# DA1470x register map
Vendor: Dialog; Series: DA1470x; File version: 1.2
CPU: CM33 r0p2, little endian, MPU, FPU, DSP, VTOR, 4 interrupt priority bits
Registers are 32-bit, read-write, reset 0x0 unless marked. A register's access mark holds for its fields unless they carry their own. Offsets are from the block's base; [hi:lo] are bit positions.

## EMMC (part 3 of 3) — EMMC registers
Base 0x30058000
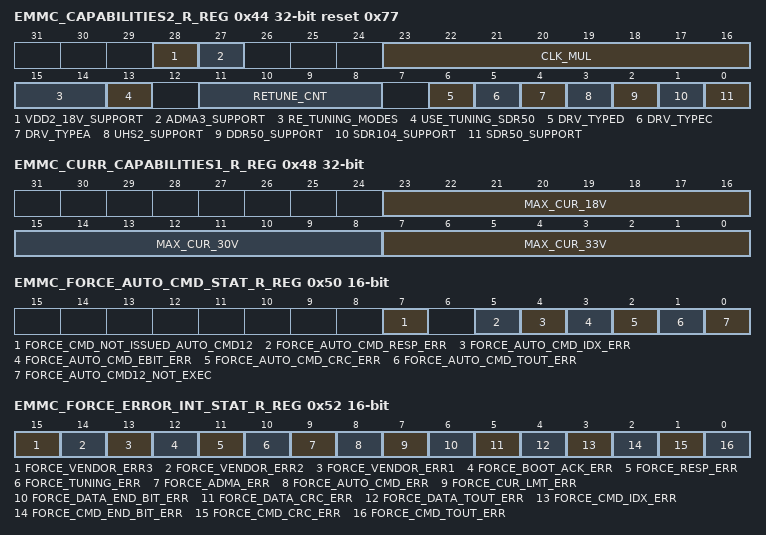
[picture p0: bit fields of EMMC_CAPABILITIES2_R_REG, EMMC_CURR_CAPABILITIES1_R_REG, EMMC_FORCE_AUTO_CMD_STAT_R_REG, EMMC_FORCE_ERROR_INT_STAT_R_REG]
0x44 EMMC_CAPABILITIES2_R_REG reset 0x77 — This register provides the Host Driver with information specific to the Host Controller implementation. The host controller may
  [28] VDD2_18V_SUPPORT ro — 1.8V VDD2 Support This bit indicates support of VDD2 for the Host System. Values: 0x0 (FALSE): 1.8V VDD2 is not Supported 0x1 (TRUE): 1.8V VDD2 is Supported
  [27] ADMA3_SUPPORT ro — ADMA3 Support This bit indicates whether the Host Controller is capable of using ADMA3. Values: 0x0 (FALSE): ADMA3 not Supported 0x1 (TRUE): ADMA3 Supported
  [23:16] CLK_MUL ro — Clock Multiplier These bits indicate the clock multiplier of the programmable clock generator. Setting these bits to 0 means that the Host Controller does not support a programmable clock generator. - 0x0: Clock Multiplier is not Supported - 0x1: Clock Multiplier M = 2 - 0x2: Clock Multiplier M = 3 - ......... - 0xFF: Clock Multiplier M = 256
  [15:14] RE_TUNING_MODES ro — Re-Tuning Modes (UHS-I only) These bits select the re-tuning method and limit the maximum data length. Values: 0x0 (MODE1): Timer 0x1 (MODE2): Timer and Re-Tuning Request (Not supported) 0x2 (MODE3): Auto Re-Tuning (for transfer) 0x3 (RSVD_MODE): Reserved
  [13] USE_TUNING_SDR50 ro — Use Tuning for SDR50 (UHS-I only)
  [11:8] RETUNE_CNT ro — Timer Count for Re-Tuning (UHS-I only) - 0x0: Re-Tuning Timer disabled - 0x1: 1 seconds - 0x2: 2 seconds - 0x3: 4 seconds - ........ - 0xB: 1024 seconds - 0xC: Reserved - 0xD: Reserved - 0xE: Reserved - 0xF: Get information from other source
  [6] DRV_TYPED ro — Driver Type D Support (UHS-I only) This bit indicates support of Driver Type D for 1.8 Signaling. Values: Description 0x0 (FALSE): Driver Type D is not supported 0x1 (TRUE): Driver Type D is supported
  [5] DRV_TYPEC ro — Driver Type C Support (UHS-I only) This bit indicates support of Driver Type C for 1.8 Signaling. Values: 0x0 (FALSE): Driver Type C is not supported 0x1 (TRUE): Driver Type C is supported
  [4] DRV_TYPEA ro — Driver Type A Support (UHS-I only) This bit indicates support of Driver Type A for 1.8 Signaling. Values: 0x0 (FALSE): Driver Type A is not supported 0x1 (TRUE): Driver Type A is supported
  [3] UHS2_SUPPORT ro — UHS-II Support (UHS-II only) This bit indicates whether Host Controller supports UHS-II. Values: 0x0 (FALSE): UHS-II is not supported 0x1 (TRUE): UHS-II is supported
  [2] DDR50_SUPPORT ro — DDR50 Support (UHS-I only) Values: 0x0 (FALSE): DDR50 is not supported 0x1 (TRUE): DDR50 is supported
  [1] SDR104_SUPPORT ro — SDR104 Support (UHS-I only) This bit mentions that SDR104 requires tuning. Values: 0x0 (FALSE): SDR104 is not supported 0x1 (TRUE): SDR104 is supported
  [0] SDR50_SUPPORT ro — SDR50 Support (UHS-I only) Thsi bit indicates that SDR50 is supported. The bit 13 (USE_TUNING_SDR50) indicates whether SDR50 requires tuning or not. Values: 0x0 (FALSE): SDR50 is not supported 0x1 (TRUE): SDR50 is supported
0x48 EMMC_CURR_CAPABILITIES1_R_REG — This register indicate the maximum current capability for each voltage, for VDD1. The value is meaningful if the Voltage Suppor
  [23:16] MAX_CUR_18V ro — Maximum Current for 1.8V This bit specifies the Maximum Current for 1.8V VDD1 power supply for the card. - 0: Get information through another method - 1: 4mA - 2: 8mA - 3: 13mA - ....... - 255: 1020mA
  [15:8] MAX_CUR_30V ro — Maximum Current for 3.0V This bit specifies the Maximum Current for 3.0V VDD1 power supply for the card. - 0: Get information through another method - 1: 4mA - 2: 8mA - 3: 13mA - ....... - 255: 1020mA
  [7:0] MAX_CUR_33V ro — Maximum Current for 3.3V This bit specifies the Maximum Current for 3.3V VDD1 power supply for the card. - 0: Get information through another method - 1: 4mA - 2: 8mA - 3: 13mA - ....... - 255: 1020mA
0x4C EMMC_CURR_CAPABILITIES2_R_REG — This register indicates the maximum current capability for each voltage (for VDD2). The value is meaningful if Voltage Support
  [7:0] MAX_CUR_VDD2_18V ro — Maximum Current for 1.8V VDD2 This bit specifies the Maximum Current for 1.8V VDD2 power supply for the UHS-II card. - 0: Get information through another method - 1: 4mA - 2: 8mA - 3: 13mA - ....... - 255: 1020mA
0x50 EMMC_FORCE_AUTO_CMD_STAT_R_REG 16-bit — The register is not a physically implemented but is an address at which the Auto CMD Error Status register can be written.This
  [7] FORCE_CMD_NOT_ISSUED_AUTO_CMD12 wo — Force Event for Command Not Issued By Auto CMD12 Error Values: 0x1 (TRUE): Command Not Issued By Auto CMD12 Error Status is set 0x0 (FALSE): Not Affected
  [5] FORCE_AUTO_CMD_RESP_ERR wo — Force Event for Auto CMD Response Error Values: 0x1 (TRUE): Auto CMD Response Error Status is set 0x0 (FALSE): Not Affected
  [4] FORCE_AUTO_CMD_IDX_ERR wo — Force Event for Auto CMD Index Error Values: 0x1 (TRUE): Auto CMD Index Error Status is set 0x0 (FALSE): Not Affected
  [3] FORCE_AUTO_CMD_EBIT_ERR wo — Force Event for Auto CMD End Bit Error Values: 0x1 (TRUE): Auto CMD End Bit Error Status is set 0x0 (FALSE): Not Affected
  [2] FORCE_AUTO_CMD_CRC_ERR wo — Force Event for Auto CMD CRC Error Values: 0x1 (TRUE): Auto CMD CRC Error Status is set 0x0 (FALSE): Not Affected
  [1] FORCE_AUTO_CMD_TOUT_ERR wo — Force Event for Auto CMD Timeout Error Values: 0x1 (TRUE): Auto CMD Timeout Error Status is set 0x0 (FALSE): Not Affected
  [0] FORCE_AUTO_CMD12_NOT_EXEC wo — Force Event for Auto CMD12 Not Executed Values: 0x1 (TRUE): Auto CMD12 Not Executed Status is set 0x0 (FALSE): Not Affected
0x52 EMMC_FORCE_ERROR_INT_STAT_R_REG 16-bit — This register is not physically implemented but is an address at which the Error Interrupt Status register can be written. The
  [15] FORCE_VENDOR_ERR3 wo — This bit (FORCE_VENDOR_ERR3) of the FORCE_ERROR_INT_STAT_R register is reserved. It always returns 0.
  [14] FORCE_VENDOR_ERR2 wo — This bit (FORCE_VENDOR_ERR2) of the FORCE_ERROR_INT_STAT_R register is reserved. It always returns 0.
  [13] FORCE_VENDOR_ERR1 wo — This bit (FORCE_VENDOR_ERR1) of the FORCE_ERROR_INT_STAT_R register is reserved. It always returns 0.
  [12] FORCE_BOOT_ACK_ERR wo — Force Event for Boot Ack error Values: 0x0 (FALSE): Not Affected 0x1 (TRUE): Boot ack Error Status is set
  [11] FORCE_RESP_ERR wo — Force Event for Response Error (SD Mode only) Values: 0x0 (FALSE): Not Affected 0x1 (TRUE): Response Error Status is set
  [10] FORCE_TUNING_ERR wo — Force Event for Tuning Error (UHS-I Mode only)
  [9] FORCE_ADMA_ERR wo — Force Event for ADMA Error Values: 0x0 (FALSE): Not Affected 0x1 (TRUE): ADMA Error Status is set
  [8] FORCE_AUTO_CMD_ERR wo — Force Event for Auto CMD Error (SD/eMMC Mode only) Values: 0x0 (FALSE): Not Affected 0x1 (TRUE): ADMA Error Status is set
  [7] FORCE_CUR_LMT_ERR wo — Force Event for Current Limit Error Values: 0x0 (FALSE): Not Affected 0x1 (TRUE): Current Limit Error Status is set
  [6] FORCE_DATA_END_BIT_ERR wo — Force Event for Data End Bit Error (SD/eMMC Mode only) Values: 0x0 (FALSE): Not Affected 0x1 (TRUE): Data End Bit Error Status is set
  [5] FORCE_DATA_CRC_ERR wo — Force Event for Data CRC Error (SD/eMMC Mode only) Values: 0x0 (FALSE): Not Affected 0x1 (TRUE): Data CRC Error Status is set
  [4] FORCE_DATA_TOUT_ERR wo — Force Event for Data Timeout Error (SD/eMMC Mode only) Values: 0x0 (FALSE): Not Affected 0x1 (TRUE): Data Timeout Error Status is set
  [3] FORCE_CMD_IDX_ERR wo — Force Event for Command Index Error (SD/eMMC Mode only) Values: 0x0 (FALSE): Not Affected 0x1 (TRUE): Command Index Error Status is set
  [2] FORCE_CMD_END_BIT_ERR wo — Force Event for Command End Bit Error (SD/eMMC Mode only) Values: 0x0 (FALSE): Not Affected 0x1 (TRUE): Command End Bit Error Status is set
  [1] FORCE_CMD_CRC_ERR wo — Force Event for Command CRC Error (SD/eMMC Mode only) Values: 0x0 (FALSE): Not Affected 0x1 (TRUE): Command CRC Error Status is set
  [0] FORCE_CMD_TOUT_ERR wo — Force Event for Command Timeout Error (SD/eMMC Mode only) Values: 0x0 (FALSE): Not Affected 0x1 (TRUE): Command Timeout Error Status is set
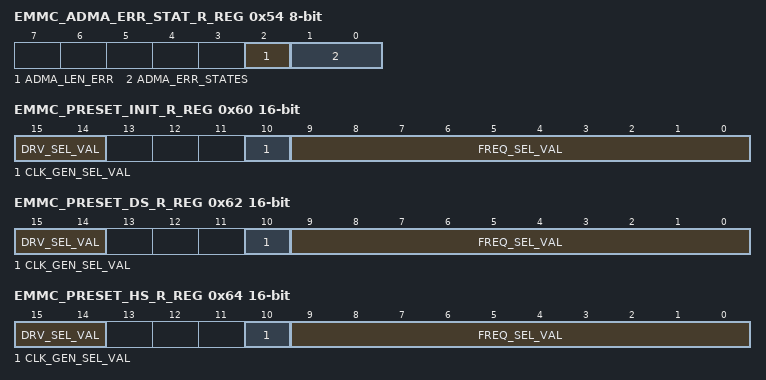
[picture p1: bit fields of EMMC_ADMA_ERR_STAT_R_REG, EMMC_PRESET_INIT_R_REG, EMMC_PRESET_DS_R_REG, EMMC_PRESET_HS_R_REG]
0x54 EMMC_ADMA_ERR_STAT_R_REG 8-bit — This register stores the ADMA state during an ADMA error. This register is applicable for an SD/eMMC/UHS-II mode.
  [2] ADMA_LEN_ERR ro — ADMA Length Mismatch Error States This error occurs in the following instances: - While the Block Count Enable is being set, the total data length specified by the Descriptor table is different from that specified by the Block Count and Block Length - When the total data length cannot be divided by the block length Values: 0x0 (NO_ERR): No Error 0x1 (ERROR): Error
  [1:0] ADMA_ERR_STATES ro — ADMA Error States These bits indicate the state of ADMA when an error occurs during ADMA data transfer. Values: 0x0 (ST_STOP): Stop DMA - SYS_ADR register points to a location next to the error descriptor 0x1 (ST_FDS): Fetch Descriptor - SYS_ADR register points to the error descriptor 0x2 (UNUSED): Never set this state 0x3 (ST_TFR): Transfer Data - SYS_ADR register points to a location next to the error descriptor
0x58 EMMC_ADMA_SA_LOW_R_REG (reset mask 0x7FFFFFFF) — This register holds the lower 32-bit system address for DMA transfer. This register is applicable for an SD/eMMC/UHS-II mode.
  [31:0] ADMA_SA_LOW — ADMA System Address These bits indicate the lower 32 bits of the ADMA system address. - SDMA: If Host Version 4 Enable is set to 1, this register stores the system address of the data location - ADMA2: This register stores the byte address of the executing command of the descriptor table - ADMA3: This register is set by ADMA3. ADMA2 increments the address of this register that points to the next line, every time a Descriptor line is fetched.
0x60 EMMC_PRESET_INIT_R_REG 16-bit — This register defines Preset Value for Initialization in SD/eMMC mode.
  [15:14] DRV_SEL_VAL ro — Driver Strength Select Value These bits indicate that the Driver strength is supported by 1.8V signaling bus speed modes. These bits are meaningless for 3.3V signaling. Values: 0x0 (TYPEB): Driver Type B is selected 0x1 (TYPEA): Driver Type A is selected 0x2 (TYPEC): Driver Type C is selected 0x3 (TYPED): Driver Type D is selected
  [10] CLK_GEN_SEL_VAL ro — Clock Generator Select Value This bit is effective when the Host Controller supports a programmable clock generator. Values: 0x0 (FALSE): Host Controller Ver2.0 Compatible Clock Generator 0x1 (PROG): Programmable Clock Generator
  [9:0] FREQ_SEL_VAL ro — SDCLK/RCLK Frequency Select Value 10-bit preset value to be set in SDCLK/RCLK Frequency Select field of the Clock Control register described by a Host System.
0x62 EMMC_PRESET_DS_R_REG 16-bit — This register defines Preset Value for Default Speed mode in SD mode.
  [15:14] DRV_SEL_VAL ro — Driver Strength Select Value These bits indicate the Driver strength value supported by 1.8V signaling bus speed modes. This field is meaningless for the Default speed mode as it uses 3.3V signaling. Values: 0x0 (TYPEB): Driver Type B is selected 0x1 (TYPEA): Driver Type A is selected 0x2 (TYPEC): Driver Type C is selected 0x3 (TYPED): Driver Type D is selected
  [10] CLK_GEN_SEL_VAL ro — Clock Generator Select Value This bit is effective when Host Controller supports programmable clock generator. Values: 0x0 (FALSE): Host Controller Ver2.0 Compatible Clock Generator 0x1 (PROG): Programmable Clock Generator
  [9:0] FREQ_SEL_VAL ro — SDCLK/RCLK Frequency Select Value 10-bit preset value to be set in SDCLK/RCLK Frequency Select field of the Clock Control register described by a Host System.
0x64 EMMC_PRESET_HS_R_REG 16-bit — This register defines Preset Value for High Speed mode in SD mode.
  [15:14] DRV_SEL_VAL ro — Driver Strength Select Value These bits indicate the Driver strength value supported by 1.8V signaling bus speed modes. This field is meaningless for High speed mode as it uses 3.3V signaling. Values: 0x0 (TYPEB): Driver Type B is selected 0x1 (TYPEA): Driver Type A is selected 0x2 (TYPEC): Driver Type C is selected 0x3 (TYPED): Driver Type D is selected
  [10] CLK_GEN_SEL_VAL ro — Clock Generator Select Value This bit is effective when Host Controller supports programmable clock generator. Values: 0x0 (FALSE): Host Controller Ver2.0 Compatible Clock Generator 0x1 (PROG): Programmable Clock Generator
  [9:0] FREQ_SEL_VAL ro — SDCLK/RCLK Frequency Select Value 10-bit preset value to be set in SDCLK/RCLK Frequency Select field of the Clock Control register described by a Host System.
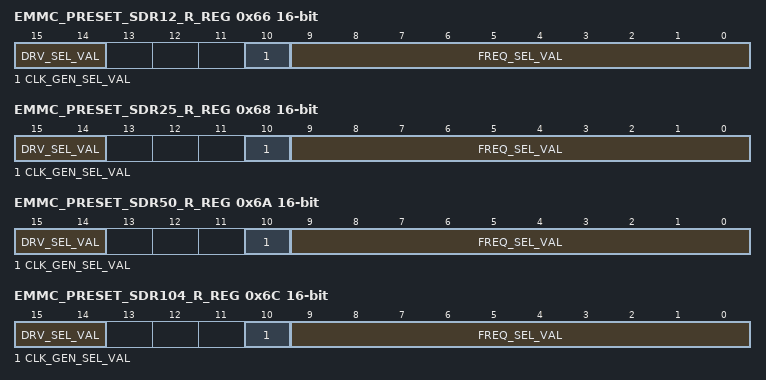
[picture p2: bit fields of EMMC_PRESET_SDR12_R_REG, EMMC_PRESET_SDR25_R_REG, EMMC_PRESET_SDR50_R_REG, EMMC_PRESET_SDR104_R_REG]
0x66 EMMC_PRESET_SDR12_R_REG 16-bit — This register defines Preset Value for SDR12 and Legacy speed mode in SD and eMMC mode respectively.
  [15:14] DRV_SEL_VAL ro — Driver Strength Select Value These bits indicate the Driver strength value supported for the SDR12 bus speed mode. These bits are meaningless for 3.3V signaling. Values: 0x0 (TYPEB): Driver Type B is selected 0x1 (TYPEA): Driver Type A is selected 0x2 (TYPEC): Driver Type C is selected 0x3 (TYPED): Driver Type D is selected
  [10] CLK_GEN_SEL_VAL ro — Clock Generator Select Value This bit is effective when Host Controller supports programmable clock generator Values: 0x0 (FALSE): Host Controller Ver2.0 Compatible Clock Generator 0x1 (PROG): Programmable Clock Generator
  [9:0] FREQ_SEL_VAL ro — SDCLK/RCLK Frequency Select Value 10-bit preset value to be set in SDCLK/RCLK Frequency Select field of the Clock Control register described by a Host System.
0x68 EMMC_PRESET_SDR25_R_REG 16-bit — This register defines Preset Value for SDR25 and High Speed SDR speed mode in SD and eMMC mode respectively.
  [15:14] DRV_SEL_VAL ro — Driver Strength Select Value These bits indicate the Driver strength value supported for the SDR25 bus speed mode. These bits are meaningless for 3.3V signaling. Values: 0x0 (TYPEB): Driver Type B is selected 0x1 (TYPEA): Driver Type A is selected 0x2 (TYPEC): Driver Type C is selected 0x3 (TYPED): Driver Type D is selected
  [10] CLK_GEN_SEL_VAL ro — Clock Generator Select Value This bit is effective when Host Controller supports programmable clock generator. Values: 0x0 (FALSE): Host Controller Ver2.0 Compatible Clock Generator 0x1 (PROG): Programmable Clock Generator
  [9:0] FREQ_SEL_VAL ro — SDCLK/RCLK Frequency Select Value 10-bit preset value to be set in SDCLK/RCLK Frequency Select field of the Clock Control register described by a Host System.
0x6A EMMC_PRESET_SDR50_R_REG 16-bit — This register defines Preset Value for SDR50 speed mode in SD mode.
  [15:14] DRV_SEL_VAL ro — Driver Strength Select Value These bits indicate Driver strength value supported for SDR50 bus speed mode. These bits are meaningless for 3.3V signaling. Values: 0x0 (TYPEB): Driver Type B is selected 0x1 (TYPEA): Driver Type A is selected 0x2 (TYPEC): Driver Type C is selected 0x3 (TYPED): Driver Type D is selected
  [10] CLK_GEN_SEL_VAL ro — Clock Generator Select Value This bit is effective when Host Controller supports programmable clock generator. Values: 0x0 (FALSE): Host Controller Ver2.0 Compatible Clock Generator 0x1 (PROG): Programmable Clock Generator
  [9:0] FREQ_SEL_VAL ro — SDCLK/RCLK Frequency Select Value 10-bit preset value to be set in SDCLK/RCLK Frequency Select field of the Clock Control register described by a Host System.
0x6C EMMC_PRESET_SDR104_R_REG 16-bit — This register defines Preset Value for SDR104 and HS200 speed modes in the SD and eMMC modes, respectively.
  [15:14] DRV_SEL_VAL ro — Driver Strength Select Value These bits indicate Driver strength value supported for SDR104 bus speed mode. These bits are meaningless for 3.3V signaling. Values: 0x0 (TYPEB): Driver Type B is selected 0x1 (TYPEA): Driver Type A is selected 0x2 (TYPEC): Driver Type C is selected 0x3 (TYPED): Driver Type D is selected
  [10] CLK_GEN_SEL_VAL ro — Clock Generator Select Value This bit is effective when Host Controller supports programmable clock generator. Values: 0x0 (FALSE): Host Controller Ver2.0 Compatible Clock Generator 0x1 (PROG): Programmable Clock Generator
  [9:0] FREQ_SEL_VAL ro — SDCLK/RCLK Frequency Select Value These bits specify a 10-bit preset value that must be set in the SDCLK/RCLK Frequency Select field of the Clock Control register described by a Host System.
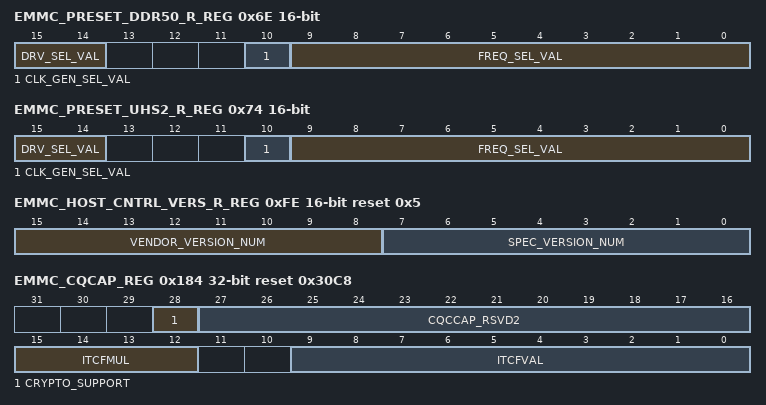
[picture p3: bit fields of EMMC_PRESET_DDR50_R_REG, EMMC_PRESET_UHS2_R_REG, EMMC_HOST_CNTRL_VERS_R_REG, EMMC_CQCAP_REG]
0x6E EMMC_PRESET_DDR50_R_REG 16-bit — This register defines the Preset Value for DDR50 and High Speed DDR speed modes in the SD and eMMC modes, respectively.
  [15:14] DRV_SEL_VAL ro — Driver Strength Select Value These bits indicate Driver strength value supported for DDR50 bus speed mode. These bits are meaningless for 3.3V signaling. Values: 0x0 (TYPEB): Driver Type B is selected 0x1 (TYPEA): Driver Type A is selected 0x2 (TYPEC): Driver Type C is selected 0x3 (TYPED): Driver Type D is selected
  [10] CLK_GEN_SEL_VAL ro — Clock Generator Select Value This bit is effective when Host Controller supports programmable clock generator. Values: 0x0 (FALSE): Host Controller Ver2.0 Compatible Clock Generator 0x1 (PROG): Programmable Clock Generator
  [9:0] FREQ_SEL_VAL ro — SDCLK/RCLK Frequency Select Value These bits specify a 10-bit preset value that must be set in the SDCLK/RCLK Frequency Select field of the Clock Control register, as described by a Host System.
0x74 EMMC_PRESET_UHS2_R_REG 16-bit — This register is used to hold the preset value for UHS-II and HS400 speed modes in the SD and eMMC modes, respectively.
  [15:14] DRV_SEL_VAL ro — Driver Strength Select Value These bits indicate the Driver strength value supported by 1.8V signaling bus speed modes in the SD mode. This field is meaningless for UHS-II mode. In eMMC mode, these bits can be used for selecting the Drive strength value for HS400 mode. Values: 0x0 (TYPEB): Driver Type B is selected 0x1 (TYPEA): Driver Type A is selected 0x2 (TYPEC): Driver Type C is selected 0x3 (TYPED): Driver Type D is selected
  [10] CLK_GEN_SEL_VAL ro — Clock Generator Select Value This bit is effective when the Host Controller supports a programmable clock generator. Values: 0x0 (FALSE): Host Controller Ver2.0 Compatible Clock Generator 0x1 (PROG): Programmable Clock Generator
  [9:0] FREQ_SEL_VAL ro — SDCLK/RCLK Frequency Select Value These bits specify the 10-bit preset value that must be set in the SDCLK/RCLK Frequency Select field of the Clock Control register, as described by a Host System.
0xE6 EMMC_P_EMBEDDED_CNTRL_REG 16-bit reset 0xF6C — This register points to the location of UHS-II embedded control registers.
  [11:0] REG_OFFSET_EMBEDDED_CNTRL_ADDR ro — Offset Address of Embedded Control register.
0xE8 EMMC_P_VENDOR_SPECIFIC_AREA_REG 16-bit reset 0x500 — This register used as a pointer for the Vendor Specific Area 1.
  [11:0] REG_OFFSET_ADDR_VENDOR ro — Base offset Address for Vendor-Specific registers.
0xEA EMMC_P_VNDR2_SPECIFIC_AREA_REG 16-bit reset 0x180 — This register is used as a pointer for the Vendor Specific Area 2.
  [15:0] REG_OFFSET_ADDR_VNDR2 ro — Base offset Address for Command Queuing registers.
0xFC EMMC_SLOT_INTR_STATUS_R_REG 16-bit — This register indicates the Interrupt status of each slot.
  [7:0] INTR_SLOT ro — Interrupt signal for each Slot These status bits indicate the logical OR of Interrupt signal and Wakeup signal for each slot. A maximum of 8 slots can be defined. If one interrupt signal is associated with multiple slots, the Host Driver can identify the interrupt that is generated by reading these bits. By a power on reset or by setting Software Reset For All bit, the interrupt signals are de-asserted and this status reads 00h. - Bit 00: Slot 1 - Bit 01: Slot 2 - Bit 02: Slot 3 - .......... - .......... - Bit 07: Slot 8 Note: MSHC Host Controller support single card slot. This register shall always return 0.
0xFE EMMC_HOST_CNTRL_VERS_R_REG 16-bit reset 0x5 — This register is used to indicate the Host Controller Version number.
  [15:8] VENDOR_VERSION_NUM ro — Vendor Version Number This field is reserved for the vendor version number. Host Driver must not use this status.
  [7:0] SPEC_VERSION_NUM ro — Specification Version Number These bits indicate the Host controller specification version. The upper and lower 4-bits indicate the version. Values 0x06-0xFF are reserved. Values: 0x0 (VER_1_00): SD Host Controller Specification Version 1.00 0x1 (VER_2_00): SD Host Controller Specification Version 2.00 0x2 (VER_3_00): SD Host Controller Specification Version 3.00 0x3 (VER_4_00): SD Host Controller Specification Version 4.00 0x4 (VER_4_10): SD Host Controller Specification Version 4.10 0x5 (VER_4_20): SD Host Controller Specification Version 4.20
0x184 EMMC_CQCAP_REG reset 0x30C8 — This register indicates the capabilities of the command queuing engine.
  [28] CRYPTO_SUPPORT ro — Crypto Support This bit indicates whether the Host Controller supports cryptographic operations. Values: 0x0 (FALSE): Crypto not Supported 0x1 (TRUE): Crypto Supported
  [27:16] CQCCAP_RSVD2 ro — These bits [27:16] of the CQCAP register are reserved. They always return 0.
  [15:12] ITCFMUL ro — Internal Timer Clock Frequency Multiplier (ITCFMUL) This field indicates the frequency of the clock used for interrupt coalescing timer and for determining the SQS polling period. See ITCFVAL definition for details. Values 0x5 to 0xF are reserved. Values: 0x0 (CLK_1KHz): 1KHz clock 0x1 (CLK_10KHz): 10KHz clock 0x2 (CLK_100KHz): 100KHz clock 0x3 (CLK_1MHz): 1MHz clock 0x4 (CLK_10MHz): 10MHz clock
  [9:0] ITCFVAL ro — Internal Timer Clock Frequency Value (ITCFVAL) This field scales the frequency of the timer clock provided by ITCFMUL. The Final clock frequency of actual timer clock is calculated as ITCFVAL* ITCFMUL.
0x500 EMMC_MSHC_VER_ID_R_REG reset 0x3138302A (reset mask 0x7FFFFFFF) — This register reflects the current release number of DWC_mshc/DWC_mshc_lite.
  [31:0] MSHC_VER_ID ro — Current release number This field indicates the Synopsys DesignWare Cores DWC_mshc/DWC_mshc_lite current release number that is read by an application. An application reading this register in conjunction with the MSHC_VER_TYPE_R register, gathers details of the current release.
0x504 EMMC_MSHC_VER_TYPE_R_REG reset 0x67612A2A (reset mask 0x7FFFFFFF) — This register reflects the current release type of DWC_mshc/DWC_mshc_lite.
  [31:0] MSHC_VER_TYPE ro — Current release type This field indicates the Synopsys DesignWare Cores DWC_mshc/DWC_mshc_lite current release type that is read by an application. An application reading this register in conjunction with the MSHC_VER_ID_R register, gathers details of the current release.
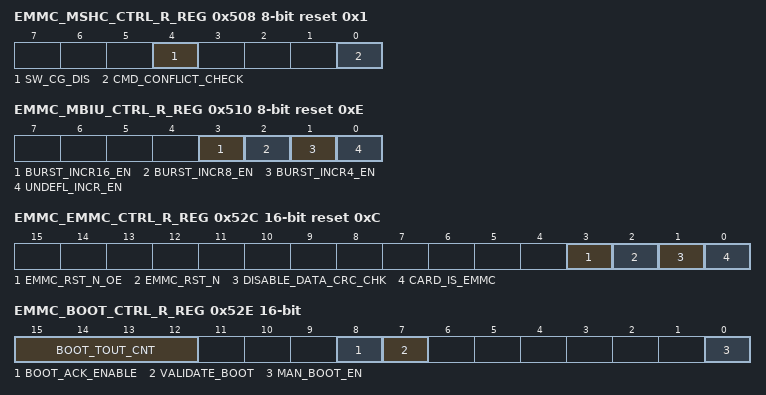
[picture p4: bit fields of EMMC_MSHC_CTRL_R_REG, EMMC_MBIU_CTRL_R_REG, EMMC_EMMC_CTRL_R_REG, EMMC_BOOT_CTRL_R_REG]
0x508 EMMC_MSHC_CTRL_R_REG 8-bit reset 0x1 — This register is used to control the operation of MSHC Host Controller.
  [4] SW_CG_DIS — Internal clock gating disable control This bit must be used to disable IP's internal clock gating when required. when disabled clocks are not gated. Clocks to the core (except hclk) must be stopped when programming this bit. Values: 0x0 (ENABLE): Internal clock gates are active and clock gating is controlled internally 0x1 (DISABLE): Internal clock gating is disabled, clocks are not gated internally
  [0] CMD_CONFLICT_CHECK — Command conflict check This bit enables command conflict check. Note: DWC_mshc controller monitors the CMD line whenever a command is issued and checks whether the value driven on sd_cmd_out matches the value on sd_cmd_in at next subsequent edge of cclk_tx to determine command conflict error. This bit is cleared only if the feed back delay (including IO Pad delay) is more than (t_card_clk_period - t_setup), where t_setup is the setup time of a flop in DWC_mshc. The I/O pad delay is consistent across CMD and DATA lines, and it is within the value: (2*t_card_clk_period - t_setup) Values: 0x0 (DISABLE_CMD_CONFLICT_CHK): Disable command conflict check 0x1 (CMD_CONFLICT_CHK_LAT1): Check for command conflict after 1 card clock cycle
0x510 EMMC_MBIU_CTRL_R_REG 8-bit reset 0xE — This register is used to select the valid burst types that the AHB Master bus interface can generate. When more than one bit
  [3] BURST_INCR16_EN — INCR16 Burst Controls generation of INCR16 transfers on Master interface. Values: 0x0 (FALSE): AHB INCR16 burst type is not generated on Master I/F 0x1 (TRUE): AHB INCR16 burst type can be generated on Master I/F
  [2] BURST_INCR8_EN — INCR8 Burst Controls generation of INCR8 transfers on Master interface. Values: 0x0 (FALSE): AHB INCR8 burst type is not generated on Master I/F 0x1 (TRUE): AHB INCR8 burst type can be generated on Master I/F
  [1] BURST_INCR4_EN — INCR4 Burst Controls generation of INCR4 transfers on Master interface. Values: 0x0 (FALSE): AHB INCR4 burst type is not generated on Master I/F 0x1 (TRUE): AHB INCR4 burst type can be generated on Master I/F
  [0] UNDEFL_INCR_EN — Undefined INCR Burst Controls generation of undefined length INCR transfer on Master interface. Values: 0x0 (FALSE): Undefined INCR type burst is the least preferred burst on AHB Master I/F 0x1 (TRUE): Undefined INCR type burst is the most preferred burst on AHB Master I/F
0x52C EMMC_EMMC_CTRL_R_REG 16-bit reset 0xC — This register is used to control the eMMC operation.
  [3] EMMC_RST_N_OE — Output Enable control for EMMC Device Reset signal PAD control. This field drived sd_rst_n_oe output of DWC_mshc Values: 0x1 (ENABLE): sd_rst_n_oe is 1 0x0 (DISABLE): sd_rst_n_oe is 0
  [2] EMMC_RST_N — EMMC Device Reset signal control. This register field controls the sd_rst_n output of DWC_mshc Values: 0x1 (RST_DEASSERT): Reset to eMMC device is deasserted 0x0 (RST_ASSERT): Reset to eMMC device asserted (active low)
  [1] DISABLE_DATA_CRC_CHK — Disable Data CRC Check This bit controls masking of CRC16 error for Card Write in eMMC mode. This is useful in bus testing (CMD19) for an eMMC device. In bus testing, an eMMC card does not send CRC status for a block, which may generate CRC error. This CRC error can be masked using this bit during bus testing. Values: 0x1 (DISABLE): DATA CRC check is disabled 0x0 (ENABLE): DATA CRC check is enabled
  [0] CARD_IS_EMMC — eMMC Card present This bit indicates the type of card connected. An application program this bit based on the card connected to MSHC. Values: 0x1 (EMMC_CARD): Card connected to MSHC is an eMMC card 0x0 (NON_EMMC_CARD): Card connected to MSHC is a non-eMMC card
0x52E EMMC_BOOT_CTRL_R_REG 16-bit — This register is used to control the eMMC Boot operation.
  [15:12] BOOT_TOUT_CNT — Boot Ack Timeout Counter Value. This value determines the interval by which boot ack timeout (50 ms) is detected when boot ack is expected during boot operation. - 0xF : Reserved - 0xE : TMCLK x 2^27 - .. - ............ - 0x1 : TMCLK x 2^14 - 0x0 : TMCLK x 2^13
  [8] BOOT_ACK_ENABLE — Boot Acknowledge Enable When this bit set, DWC_mshc checks for boot acknowledge start pattern of 0-1-0 during boot operation. This bit is applicable for both mandatory and alternate boot mode. Values: 0x1 (TRUE): Boot Ack enable 0x0 (FALSE): Boot Ack disable
  [7] VALIDATE_BOOT wo — Validate Mandatory Boot Enable bit This bit is used to validate the MAN_BOOT_EN bit. Values: 0x1 (TRUE): Validate Mandatory boot enable bit 0x0 (FALSE): Ignore Mandatory boot Enable bit
  [0] MAN_BOOT_EN — Mandatory Boot Enable This bit is used to initiate the mandatory boot operation. The application sets this bit along with VALIDATE_BOOT bit. Writing 0 is ignored. The DWC_mshc clears this bit after the boot transfer is completed or terminated. Values: 0x1 (MAN_BOOT_EN): Mandatory boot enable 0x0 (MAN_BOOT_DIS): Mandatory boot disable
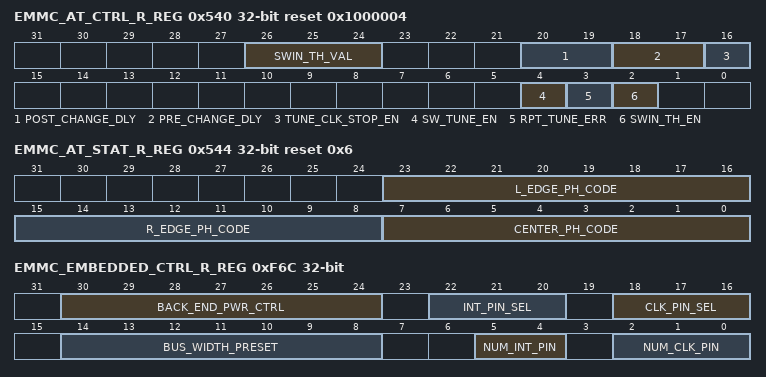
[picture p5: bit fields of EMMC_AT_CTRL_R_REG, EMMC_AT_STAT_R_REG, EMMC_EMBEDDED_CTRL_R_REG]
0x540 EMMC_AT_CTRL_R_REG reset 0x1000004 — This register controls some aspects of tuning and auto-tuning features. Do not program this register when HOST_CTRL2_R.SAMPLE_C
  [26:24] SWIN_TH_VAL — Sampling window threshold value setting The maximum value that can be set here depends on the length of delayline used for tuning. A delayLine with 128 taps can use values from 0x0 to 0x7F. This field is valid only when SWIN_TH_EN is '1'. Should be programmed only when SAMPLE_CLK_SEL is '0' - 0x0 : Threshold values is 0x1, windows of length 1 tap and above can be selected as sampling window. - 0x1 : Threshold values is 0x2, windows of length 2 taps and above can be selected as sampling window. - 0x2 : Threshold values is 0x1, windows of length 3 taps and above can be selected as sampling window. - ........ - 0x7F : Threshold values is 0x1, windows of length 127 taps and above can be selected as sampling window.
  [20:19] POST_CHANGE_DLY — Time taken for phase switching and stable clock output. Specifies the maximum time (in terms of cclk cycles) that the delay line can take to switch its output phase after a change in tuning_cclk_sel or autotuning_cclk_sel. Values: 0x0 (LATENCY_LT_1): Less than 1-cycle latency 0x1 (LATENCY_LT_2): Less than 2-cycle latency 0x2 (LATENCY_LT_3): Less than 3-cycle latency 0x3 (LATENCY_LT_4): Less than 4-cycle latency
  [18:17] PRE_CHANGE_DLY — Maximum Latency specification between cclk_tx and cclk_rx. Values: 0x0 (LATENCY_LT_1): Less than 1-cycle latency 0x1 (LATENCY_LT_2): Less than 2-cycle latency 0x2 (LATENCY_LT_3): Less than 3-cycle latency 0x3 (LATENCY_LT_4): Less than 4-cycle latency
  [16] TUNE_CLK_STOP_EN — Clock stopping control for Tuning and auto-tuning circuit. When enabled, clock gate control output of DWC_mshc (clk2card_on) is pulled low before changing phase select codes on tuning_cclk_sel and autotuning_cclk_sel. This effectively stops the Device/Card clock, cclk_rx and also drift_cclk_rx. Changing phase code when clocks are stopped ensures glitch free phase switching. Set this bit to 0 if the PHY or delayline can guarantee glitch free switching. Values: 0x1 (ENABLE_CLK_STOPPING): Clocks stopped during phase code change 0x0 (DISABLE_CLK_STOPPING): Clocks not stopped. PHY ensures glitch free phase switching.
  [4] SW_TUNE_EN — This fields enables software-managed tuning flow. Values: 0x1 (SW_TUNING_ENABLE): Software-managed tuning enabled. AT_STAT_R.CENTER_PH_CODE Field is now writable. 0x0 (SW_TUNING_DISABLE): Software-managed tuning disabled.
  [3] RPT_TUNE_ERR — Framing errors are not generated when executing tuning. This debug bit allows users to report these errors. Values: 0x1 (DEBUG_ERRORS): Debug mode for reporting framing errors 0x0 (ERRORS_DISABLED): Default mode where as per SD-HCI no errors are reported.
  [2] SWIN_TH_EN — Sampling window Threshold enable Selects the tuning mode Field should be programmed only when SAMPLE_CLK_SEL is '0' Values: 0x1 (THRESHOLD_MODE): Tuning engine selects the first complete sampling window that meets the threshold set by SWIN_TH_VAL field 0x0 (LARGEST_WIN_MODE): Tuning engine sweeps all taps and settles at the largest window
0x544 EMMC_AT_STAT_R_REG reset 0x6 — Register to read the Center, Left and Right codes used by tuning and auto-tuning engines. Center code field is also used for so
  [23:16] L_EDGE_PH_CODE ro — Left Edge Phase code. Reading this field returns the phase code value used by Auto-tuning engine to sample data on Left edge of sampling window.
  [15:8] R_EDGE_PH_CODE ro — Right Edge Phase code. Reading this field returns the phase code value used by Auto-tuning engine to sample data on Right edge of sampling window.
  [7:0] CENTER_PH_CODE — Centered Phase code. Reading this field returns the current value on tuning_cclk_sel output. Setting AT_CTRL_R.SW_TUNE_EN enables software to write to this field and its contents are reflected on tuning_cclk_sel.
0xF6C EMMC_EMBEDDED_CTRL_R_REG — This register controls the embedded device. When the Host Controller is connected to a removable device, this register is not u
  [30:24] BACK_END_PWR_CTRL — Back-End Power Control (SD Mode) Each bit of this field controls back-end power supply for an embedded device. - 0 : Back-End Power is off - 1 : Back-End Power is supplied D24 : Back-End Power for Device 1 D25 : Back-End Power for Device 2 D26 : Back-End Power for Device 3 D27 : Back-End Power for Device 4 D28 : Back-End Power for Device 5 D29 : Back-End Power for Device 6 D30 : Back-End Power for Device 7
  [22:20] INT_PIN_SEL — Interrupt Pin Select These bits enable the interrupt pin inputs. - 000 : Interrupts (INT_A,INT_B,INT_C) are disabled - xx1 : INT_A is enabled - x1x : INT_B is enabled - 1xx : INT_C is enabled
  [18:16] CLK_PIN_SEL — Clock Pin Select (SD Mode) This bit is selected by one of clock pin outputs. - 0x0 : Clock pins are disabled - 0x1 : CLK[1] is selected - 0x2 : CLK[2] is selected - . . - . . - . . - 0x7 : CLK[7] is selected
  [14:8] BUS_WIDTH_PRESET ro — Bus Width Preset (SD Mode) Each bit of this field specifies the bus width for each embedded device. The shared bus supports mixing of 4-bit and 8-bit bus width devices. - D08 : Bus Width Preset for Device 1 - D09 : Bus Width Preset for Device 2 - D10 : Bus Width Preset for Device 3 - D11 : Bus Width Preset for Device 4 - D12 : Bus Width Preset for Device 5 - D13 : Bus Width Preset for Device 6 - D14 : Bus Width Preset for Device 7 Function of each bit is defined as follows: - 0 : 4-bit bus width mode - 1 : 8-bit bus width mode
  [5:4] NUM_INT_PIN ro — Number of Interrupt Input Pins This field indicates support of interrupt input pins for an embedded system.
  [2:0] NUM_CLK_PIN ro — Number of Clock Pins (SD Mode) This field indicates support of clock pins to select one of devices for shared bus system. Up to 7 clock pins can be supported. - 0x0 : Shared bus is not supported - 0x1 : 1 SDCLK is supported - 0x2 - 2 SDCLK is supported - . . - . . - . . - 0x7 : 7 SDCLK is supported
